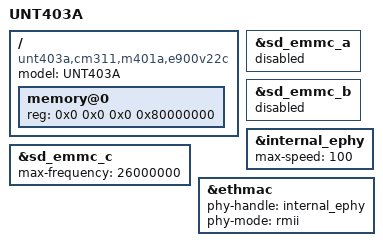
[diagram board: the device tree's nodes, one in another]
// SPDX-License-Identifier: (GPL-2.0+ OR MIT)
/*
 * Copyright (c) 2018 Amlogic, Inc. All rights reserved.
 * Created by 7Ji.
 */

/dts-v1/;

#include "meson-g12a-u200.dts"

/ {
	compatible = "unt403a,cm311,m401a,e900v22c", "amlogic,g12a";
	model = "UNT403A";

	memory@0 {
		device_type = "memory";
		reg = <0x0 0x0 0x0 0x80000000>;
	};
};

/* SDIO */
&sd_emmc_a { 
	// We don't need the wireless card when booting
	status = "disabled";
};

/* SD card */
&sd_emmc_b {
	// UNT403A is impossible to mod with SD card slot so disable it
	status = "disabled";
};

/* eMMC */
&sd_emmc_c {
	status = "okay";
	// Hack from https://github.com/KryptonLee/u-boot-e900v22c/commit/9d9a471c720259a8c541c5b6ccbbb57c82bf30c9, cite: "The eMMC of SKYWORTH E900V22C TV-Box has MMC_HS200 and MMC_HS_52 modes in its caps, however it will lose control when the bus frequency is set to 52MHz or higher."
	/delete-property/ mmc-hs200-1_8v;
	/delete-property/ mmc-ddr-1_8v;
	max-frequency = <26000000>; 
};

&internal_ephy  {
	max-speed = <100>;
};

&ethmac {
	/delete-property/ resets;
	/delete-property/ reset-names;
	phy-handle = <&internal_ephy>;
	phy-mode = "rmii";
	status = "okay";
};
